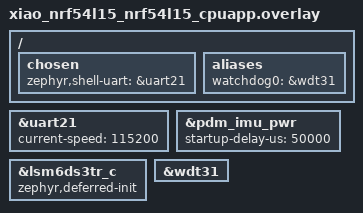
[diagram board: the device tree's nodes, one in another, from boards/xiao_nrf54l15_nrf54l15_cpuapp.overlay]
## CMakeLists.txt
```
#
# Copyright (c) 2021 Nordic Semiconductor ASA
#
# SPDX-License-Identifier: LicenseRef-Nordic-5-Clause
#

cmake_minimum_required(VERSION 3.20.0)

find_package(Zephyr HINTS $ENV{ZEPHYR_BASE})

project(nRF54l15_Bridge)

# Enable GNU STD support.
include(${ZEPHYR_CONNECTEDHOMEIP_MODULE_DIR}/config/nrfconnect/app/enable-gnu-std.cmake)

# NORDIC SDK APP START

# Include all source files that are located in the Matter common directory.
include(${ZEPHYR_NRF_MODULE_DIR}/samples/matter/common/cmake/source_common.cmake)

# Include Data Model utils
include(${ZEPHYR_NRF_MODULE_DIR}/samples/matter/common/cmake/data_model.cmake)

include(${ZEPHYR_NRF_MODULE_DIR}/samples/matter/common/cmake/zap_helpers.cmake)
ncs_get_zap_parent_dir(ZAP_PARENT_DIR)

target_include_directories(app PRIVATE
  src
  ${ZAP_PARENT_DIR}
)

target_sources(app PRIVATE
  src/app_task.cpp
  src/main.cpp
)

ncs_configure_data_model()
# NORDIC SDK APP END
```

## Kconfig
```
#
# Copyright (c) 2022 Nordic Semiconductor
#
# SPDX-License-Identifier: LicenseRef-Nordic-5-Clause
#
mainmenu "Matter nRF Connect Template Example Application"

# Sample configuration used for Thread networking
if OPENTHREAD

# Full Thread Device, not the template's minimal default.
#
# The bridge is mains-powered and hosts up to a hundred endpoints a controller
# subscribes to; it should keep its radio on and route for the mesh rather than
# sleep. An MTD cannot be a parent either, so anything downstream would have to
# reach the border router directly.
#
# This costs RAM: the router tables and the larger OpenThread library are a good
# part of why the previous project sat so close to the ceiling.
choice OPENTHREAD_NORDIC_LIBRARY_CONFIGURATION
	default OPENTHREAD_NORDIC_LIBRARY_FTD
endchoice

choice OPENTHREAD_DEVICE_TYPE
	default OPENTHREAD_FTD
endchoice

# SED with 0 dBm Thread TX output power for nRF54L15 tag
if BOARD_NRF54L15TAG

config CHIP_ENABLE_ICD_SUPPORT
	default y

config OPENTHREAD_DEFAULT_TX_POWER
	default 0

endif

endif # OPENTHREAD

config CHIP_WIFI
	default y if SHIELD_NRF7002EB2

menu "Matter bridge options"

config BRIDGE_MAX_ENDPOINTS
	int "Maximum number of bridged devices"
	default 8
	range 1 240
	help
	  Size of the bridge slot table and of the Matter dynamic endpoint
	  storage. Each slot costs RAM (endpoint record + data versions +
	  Matter attribute-storage metadata), so raising this is the main
	  lever on how many devices the board can host at once.

config BRIDGE_DEBUG_LOG
	bool "Verbose bridge debug logging"
	default y
	help
	  Emit extra informational logs from the bridge. Turn this off in
	  release builds (e.g. on RAM-constrained boards) to save memory.

menu "Bridged device types available to host"

config BRIDGE_TYPE_TEMPERATURE
	bool "Temperature sensor"
	default y

config BRIDGE_TYPE_HUMIDITY
	bool "Humidity sensor"
	default y

config BRIDGE_TYPE_ONOFF_LIGHT
	bool "On/Off light"
	default y

config BRIDGE_TYPE_CONTACT
	bool "Contact sensor"
	default y

config BRIDGE_TYPE_OCCUPANCY
	bool "Occupancy sensor"
	default y

config BRIDGE_TYPE_PRESSURE
	bool "Pressure sensor"
	default y

config BRIDGE_TYPE_FLOW
	bool "Flow sensor"
	default y

config BRIDGE_TYPE_ILLUMINANCE
	bool "Illuminance (light) sensor"
	default y

config BRIDGE_TYPE_WATER_LEAK
	bool "Water leak detector"
	default y

config BRIDGE_TYPE_ONOFF_PLUG
	bool "On/Off plug / outlet"
	default y

config BRIDGE_TYPE_DIMMABLE_LIGHT
	bool "Dimmable light"
	default y

config BRIDGE_TYPE_COLOR_LIGHT
	bool "Color temperature light"
	default y

config BRIDGE_TYPE_WINDOW_COVERING
	bool "Window covering (blinds / shades)"
	default y

config BRIDGE_TYPE_DOOR_LOCK
	bool "Door lock"
	default y

config BRIDGE_TYPE_RGB_LIGHT
	bool "Extended color (RGB) light"
	default y

config BRIDGE_TYPE_DIMMABLE_PLUG
	bool "Dimmable plug"
	default y

config BRIDGE_TYPE_THERMOSTAT
	bool "Thermostat"
	default y

config BRIDGE_TYPE_FAN
	bool "Fan"
	default y

config BRIDGE_TYPE_AIR_PURIFIER
	bool "Air purifier"
	default y

config BRIDGE_TYPE_AIR_QUALITY
	bool "Air quality sensor"
	default y

config BRIDGE_TYPE_SMOKE_CO
	bool "Smoke / CO alarm"
	default y

config BRIDGE_TYPE_WATER_VALVE
	bool "Water valve"
	default y

config BRIDGE_TYPE_WATER_FREEZE
	bool "Water freeze detector"
	default y

config BRIDGE_TYPE_RAIN
	bool "Rain sensor"
	default y

config BRIDGE_TYPE_ONOFF_SENSOR
	bool "On/Off sensor"
	default y

config BRIDGE_TYPE_MOUNTED_ONOFF
	bool "Mounted On/Off control"
	default y

config BRIDGE_TYPE_MOUNTED_DIMMER
	bool "Mounted dimmable load control"
	default y

config BRIDGE_TYPE_PUMP
	bool "Pump"
	default n

config BRIDGE_TYPE_COOKTOP
	bool "Cooktop"
	default n

config BRIDGE_TYPE_SPEAKER
	bool "Speaker (on/off + volume)"
	default n

config BRIDGE_TYPE_EXTRACTOR_HOOD
	bool "Extractor hood"
	default n

config BRIDGE_TYPE_ROOM_AC
	bool "Room air conditioner"
	default y

config BRIDGE_TYPE_HVAC_UNIT
	bool "Heating/cooling unit"
	default y

config BRIDGE_TYPE_HEAT_PUMP
	bool "Heat pump"
	default y

config BRIDGE_TYPE_WATER_HEATER
	bool "Water heater"
	default y

config BRIDGE_TYPE_SOIL
	bool "Soil sensor (moisture)"
	default y

comment "Stub device types (announced only, no functional clusters yet)"

config BRIDGE_TYPE_STUB_CONTROL
	bool "Stub: generic switch"
	default n

config BRIDGE_TYPE_STUB_ENERGY
	bool "Stub: energy devices (EVSE, solar, battery, meter, tariff, DEM)"
	default n

config BRIDGE_TYPE_STUB_APPLIANCE
	bool "Stub: appliances (vacuum, fridge, washer, dryer, dishwasher, oven...)"
	default n

config BRIDGE_TYPE_STUB_MEDIA
	bool "Stub: media devices (video players, content app)"
	default n

config BRIDGE_TYPE_STUB_CLOSURE
	bool "Stub: closures (Matter 1.5)"
	default n

config BRIDGE_TYPE_STUB_CAMERA
	bool "Stub: camera (Matter 1.5)"
	default n

endmenu # Bridged device types

menu "XIAO nRF54L15 Sense on-board sensors"
	depends on BOARD_XIAO_NRF54L15

config BRIDGE_XIAO_IMU
	bool "Vibration / drop detection from the on-board IMU (LSM6DSO)"
	# Ported switched off: the IMU is a later step of the rebuild, and pulling
	# the sensor driver in now would test two things at once.
	default n
	select SENSOR
	select I2C
	select LSM6DSL
	help
	  Samples the on-board 6-axis IMU and exposes the result as a bridged
	  occupancy (motion) endpoint. The accelerometer is used rather than the
	  microphone: it detects both shaking and an actual drop (free fall
	  followed by an impact), and it cannot be fooled by ambient noise.

if BRIDGE_XIAO_IMU

config BRIDGE_XIAO_IMU_AUTO_ENDPOINT
	bool "Create the vibration endpoint automatically on first boot"
	default y

config BRIDGE_XIAO_IMU_STACK_SIZE
	int "Stack size of the IMU sampling thread"
	default 2048
	help
	  The sampling loop takes the Matter stack lock and performs I2C
	  transfers, so it needs its own stack rather than the shared system
	  workqueue.

config BRIDGE_XIAO_IMU_PERIOD_MS
	int "Sampling period in milliseconds"
	default 50

config BRIDGE_XIAO_IMU_VIBRATION_MG
	int "Vibration threshold (milli-g deviation from 1 g at rest)"
	default 350

config BRIDGE_XIAO_IMU_FREEFALL_MG
	int "Free-fall threshold (milli-g, total acceleration)"
	default 300

config BRIDGE_XIAO_IMU_IMPACT_MG
	int "Impact threshold after free fall (milli-g)"
	default 2000

config BRIDGE_XIAO_IMU_HOLD_S
	int "How long the endpoint stays 'detected' after a trigger (seconds)"
	default 5

endif # BRIDGE_XIAO_IMU

config BRIDGE_XIAO_MIC
	bool "Build the on-board PDM microphone driver"
	default n
	select AUDIO
	select AUDIO_DMIC
	help
	  Build-time switch that pulls in the PDM microphone driver for the Sense
	  board. Nothing in the bridge consumes audio yet - vibration detection
	  uses the IMU - so this only adds the driver to the image.

endmenu # XIAO sensors

menu "Shell access"

config BRIDGE_AUX_SHELL
	bool "Serve a second shell on the other UART"
	depends on SHELL
	default n
	help
	  Zephyr binds its UART shell to `chosen { zephyr,shell-uart }` and only
	  ever creates one instance, so the two board overlays are an either/or
	  switch: commands arrive over USB or over the header pins, never both.

	  Enable this to bring up a second, independent shell on the UART named
	  by `chosen { bridge,cmd-uart }` - the overlays point it at whichever
	  port the main shell did not take. Both instances share the same command
	  set and keep their own line buffer and history, so the ESP companion on
	  the pins and a human on the USB console do not step on each other.

	  Costs roughly 3 KB of RAM (a shell thread plus its buffers).

if BRIDGE_AUX_SHELL

config BRIDGE_AUX_SHELL_PROMPT
	string "Prompt for the second shell"
	default "aux:~$ "
	help
	  Deliberately different from the main shell's "uart:~$ " so it is
	  obvious which port you are typing on.

config BRIDGE_AUX_SHELL_INIT_PRIORITY
	int "Init priority for the second shell"
	default 91
	range 0 99
	help
	  Must be higher than both the UART driver's priority and
	  SHELL_BACKEND_SERIAL_INIT_PRIORITY (which defaults to
	  APPLICATION_INIT_PRIORITY, 90), so the built-in shell finishes
	  claiming its port first.

endif # BRIDGE_AUX_SHELL

endmenu # Shell access

endmenu # Matter bridge options

source "$(ZEPHYR_CONNECTEDHOMEIP_MODULE_DIR)/config/nrfconnect/chip-module/Kconfig.features"
source "$(ZEPHYR_CONNECTEDHOMEIP_MODULE_DIR)/config/nrfconnect/chip-module/Kconfig.defaults"
source "$(ZEPHYR_NRF_MODULE_DIR)/samples/matter/common/src/Kconfig"
source "Kconfig.zephyr"
```

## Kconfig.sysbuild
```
#
# Copyright (c) 2023 Nordic Semiconductor ASA
#
# SPDX-License-Identifier: LicenseRef-Nordic-5-Clause
#

#### Radio core selection
config NRF_DEFAULT_IPC_RADIO
	default y

# Enable IEEE802.15.4 serialization to network core
# This config automatically pulls in the `overlay-802154.conf` in the ipc_radio image
config NETCORE_IPC_RADIO_IEEE802154
	default y if SOC_SERIES_NRF53 && !WIFI_NRF70

# Enable Bluetooth serialization to network core
# This config automatically pulls in the `overlay-bt_hci_ipc.conf` in the ipc_radio image
config NETCORE_IPC_RADIO_BT_HCI_IPC
	default y if SOC_SERIES_NRF53

#### Bootloader
#
# No MCUboot on the XIAO. The board has no external flash, so the secondary
# slot would have to come out of the same internal RRAM as the application, and
# DFU through it is not something this board can usefully do anyway. Left
# enabled it does not merely waste space: MCUboot itself halts in
# arch_system_halt before ever reaching the application. Building without a
# bootloader links the app at 0x0 and hands it the whole RRAM - which is what
# the previous working firmware did too.
choice BOOTLOADER
	default BOOTLOADER_NONE if BOARD_XIAO_NRF54L15
	default BOOTLOADER_MCUBOOT if !BOARD_NRF21540DK
endchoice

# Matter OTA goes with it. Sysbuild pushes CONFIG_CHIP_OTA_REQUESTOR into the
# application image (nrf/sysbuild/CMakeLists.txt), so setting it in a board
# fragment is useless - the value arrives via .config.sysbuild and wins. Without
# MCUboot the requestor fails to link on `dfu_target_mcuboot_set_buf`.
config MATTER_OTA
	default n if BOARD_XIAO_NRF54L15

if BOOTLOADER_MCUBOOT

#### DFU multi-image support
config DFU_MULTI_IMAGE_PACKAGE_BUILD
	default y

config DFU_MULTI_IMAGE_PACKAGE_APP
	default y

#### DFU network core configuration
if SOC_SERIES_NRF53

choice MCUBOOT_MODE
	default MCUBOOT_MODE_OVERWRITE_ONLY
endchoice

choice BOOT_SIGNATURE_TYPE
	default BOOT_SIGNATURE_TYPE_RSA
endchoice

config SECURE_BOOT_NETCORE
	default y

config NETCORE_APP_UPDATE
	default y

config DFU_MULTI_IMAGE_PACKAGE_NET
	default y

endif # SOC_SERIES_NRF53

endif # BOOTLOADER_MCUBOOT

#### Enable generating factory data
#
# The XIAO has no factory_data partition to write into - no external flash, and
# its layout does not carve one out - so the generator aborts during sysbuild
# configuration with "required nodelabel not found: factory_data_partition".
# The board falls back to the development certificates compiled into the
# firmware, which is what CONFIG_CHIP_FACTORY_DATA=n selects application-side.
config MATTER_FACTORY_DATA_GENERATE
	default y if !BOARD_NRF21540DK && !BOARD_XIAO_NRF54L15

# Internal flash only for nRF54L15 tag with compression
if BOARD_NRF54L15TAG

choice MCUBOOT_MODE
	default MCUBOOT_MODE_OVERWRITE_ONLY
endchoice

config MCUBOOT_COMPRESSED_IMAGE_SUPPORT
	default y

endif

# Partition Manager backwards compatibility
if PARTITION_MANAGER

if SOC_NRF54L10

config PM_MCUBOOT_PAD
	default 0x1000

endif # SOC_NRF54L10

if BOARD_NRF54L15TAG

config PM_OVERRIDE_EXTERNAL_DRIVER_CHECK
	default y

config PM_EXTERNAL_FLASH_MCUBOOT_SECONDARY
	default y

endif # BOARD_NRF54L15TAG

if BOARD_NRF54L15DK || BOARD_NRF54LM20DK

# Disable checking the external drivers for nRF54L15 and nRF54LM20 DKs.
config PM_OVERRIDE_EXTERNAL_DRIVER_CHECK
	default y

endif # BOARD_NRF54L15DK || BOARD_NRF54LM20DK

if BOOTLOADER_MCUBOOT

config PM_EXTERNAL_FLASH_MCUBOOT_SECONDARY
	default y

endif # BOOTLOADER_MCUBOOT

endif # PARTITION_MANAGER

source "share/sysbuild/Kconfig"
```

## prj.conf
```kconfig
#
# Copyright (c) 2021 Nordic Semiconductor ASA
#
# SPDX-License-Identifier: LicenseRef-Nordic-5-Clause
#

# This sample uses Kconfig.defaults to set options common for all
# samples. This file should contain only options specific for this sample
# or overrides of default values.

# Enable CHIP
CONFIG_CHIP=y
CONFIG_CHIP_PROJECT_CONFIG="src/chip_project_config.h"
CONFIG_CHIP_DEVICE_PRODUCT_NAME="Matter Template"

# Configure ZAP file name
CONFIG_NCS_SAMPLE_MATTER_ZAP_FILE_PATH="${APPLICATION_CONFIG_DIR}/src/default_zap/template.zap"

# 32768 == 0x8000 (example Product ID added temporaly,
# but it must be changed with proper PID from the list:
# https://github.com/project-chip/connectedhomeip/blob/482e6fd03196a6de45465a90003947ef4b86e0b1/docs/examples/discussion/PID_allocation_for_example_apps.md)
CONFIG_CHIP_DEVICE_PRODUCT_ID=32768
CONFIG_STD_CPP17=y

# Enable Matter pairing automatically on application start.
CONFIG_CHIP_ENABLE_PAIRING_AUTOSTART=y

# Enable Matter extended announcement and increase duration to 1 hour.
CONFIG_CHIP_BLE_EXT_ADVERTISING=y
CONFIG_CHIP_BLE_ADVERTISING_DURATION=60

# Add support for LEDs and buttons on Nordic development kits
CONFIG_DK_LIBRARY=y

# Bluetooth Low Energy configuration
CONFIG_BT_DEVICE_NAME="MatterTemplate"

# Other settings
CONFIG_THREAD_NAME=y
CONFIG_MPU_STACK_GUARD=y
CONFIG_RESET_ON_FATAL_ERROR=n
CONFIG_CHIP_LIB_SHELL=y
CONFIG_NCS_SAMPLE_MATTER_TEST_SHELL=y

# Disable NFC onboarding
CONFIG_CHIP_NFC_ONBOARDING_PAYLOAD=n

# Reduce application size
CONFIG_USE_SEGGER_RTT=n

# Factory data: off.
#
# Set here rather than in boards/xiao_nrf54l15_nrf54l15_cpuapp.conf because a
# board fragment does not win against an explicit assignment in prj.conf - the
# board file said =n and the build still came out =y.
#
# The XIAO has no factory_data partition (no external flash, and the layout
# does not carve one out), so the provider fails to compile at all:
# FactoryDataProvider.h needs DT_NODELABEL(factory_data_partition). Matter uses
# the development certificates compiled into the firmware instead.
# NOTE: CONFIG_CHIP_FACTORY_DATA=n does NOT work here. In NCS 3.4 the provider
# sits behind `choice CHIP_FACTORY_DATA_BACKEND`, whose default member selects
# CHIP_FACTORY_DATA - and a select cannot be overridden by =n in a fragment.
# Picking the "none" member of the choice is the supported way to turn it off.
# (In 3.2.3 there was no choice and plain =n was enough.)
CONFIG_CHIP_FACTORY_DATA_NONE=y
```

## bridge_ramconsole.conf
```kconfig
# Console into RAM, read out over SWD.
#
# For debugging only. Both UARTs on this board have been unreadable - the
# header pins go quiet and the USB console emits a handful of corrupt bytes at
# every baud rate - which meant Zephyr's fault dump, the one thing that says
# what actually crashed, was being written into a void. A RAM console does not
# care about clocks, pins or a debug chip's CDC: the text lands in a buffer at a
# known address and a debugger reads it out afterwards.
#
# Add as the last Extra Kconfig fragment; remove it for normal builds.
CONFIG_RAM_CONSOLE=y
CONFIG_RAM_CONSOLE_BUFFER_SIZE=4096

# The UART console must go, or it stays the active console driver and the RAM
# buffer never receives a byte - which looks exactly like "nothing was printed".
CONFIG_UART_CONSOLE=n
```

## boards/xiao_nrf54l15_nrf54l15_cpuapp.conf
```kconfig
# Seeed XIAO nRF54L15 (Sense) - application configuration.
#
# Picked up automatically by filename, no need to list it as an extra fragment.

# Factory data is switched off in prj.conf - see the note there, it has to be
# done through the backend choice rather than CONFIG_CHIP_FACTORY_DATA=n.

# CONFIG_LTO is deliberately NOT set.
#
# It was added early on to squeeze the image into MCUboot's 664 KB slot. Once
# the bootloader went away the whole RRAM became available and LTO was no
# longer needed - but it stayed, and it corrupts the linker-section table that
# net_buf pools are looked up through. The result was a BUS FAULT with
# BFAR 0xa inside pool_get_uninit on the MPSL Work thread, right after BLE
# init: net_buf_alloc_len being handed a null pool.
#
# It behaved like a memory bug - intermittent, and more frequent as the image
# grew - because that is how LTO decisions shift. Turning it off fixed it
# outright: first flash, clean boot, every time. Costs 52 KB of flash out of
# 1524 KB, which is not a trade worth revisiting.
CONFIG_ISR_TABLES_LOCAL_DECLARATION=y

# Consequences of building without MCUboot (see Kconfig.sysbuild).
#
# Matter's OTA requestor is written against MCUboot's DFU target; with no
# bootloader it still compiles but fails to link on
# `dfu_target_mcuboot_set_buf`. Both have to go together - this is a dependency
# of the bootloader choice, not a separate decision.
CONFIG_CHIP_BOOTLOADER_NONE=y
CONFIG_CHIP_OTA_REQUESTOR=n

# Shell tuning for a machine on the other end of the wire.
#
# The defaults are aimed at a person on a terminal; over a raw UART the escape
# sequences only get in the way of a parser. And `bridge add <type> <name>` or
# `bridge set <id> <v> <v2> <v3>` are long lines - the default command buffer
# truncates them.
CONFIG_SHELL_VT100_COLORS=n
CONFIG_SHELL_CMD_BUFF_SIZE=256

# The default 3168 bytes left next to nothing spare: `bridge pairing` added a
# couple of frames and the thread ran off the bottom of its own stack, taking
# the board down in MemManage on the very first call. Generating the onboarding
# codes is the deepest work any command here does, so the headroom is sized for
# that rather than for the shallowest one.
CONFIG_SHELL_STACK_SIZE=4096

# The actual cause of "the ESP sees nothing on the wire" before this board is
# paired to anything - not the board being broken, and not fixable by
# resetting either side of the link.
#
# Zephyr's shell thread runs at K_LOWEST_APPLICATION_THREAD_PRIO when nothing
# overrides it - one step above idle, below every other thread in this image.
# Zephyr's shell thread runs at K_LOWEST_APPLICATION_THREAD_PRIO when nothing
# overrides it - one step above idle, below every other thread in this image
# (BT/OpenThread sit at priorities 6-8). An uncommissioned board advertises
# over BLE continuously, which keeps those threads busy ahead of the shell on
# every scheduling decision, on a single core with no time-slicing across
# priority levels. The shell is not stuck; it simply never wins.
#
# Raised to 1 - one step below main(), clear of every BT/OpenThread thread,
# well short of the cooperative MPSL tier nothing preemptible can reach
# anyway. Verified over SWD (RAM-console build) that the node was genuinely
# losing the scheduling race, not crashed or starved outright - but the
# priority bump alone did not clear the symptom. The actual fix is
# architectural: BLE advertising now stays off until told to start (`bridge
# commission`) - see PORTING_NOTES.md and nrf_link.h's "deferred pairing"
# block. Left in place regardless: a correct, harmless improvement even
# though it was not sufficient by itself.
CONFIG_SHELL_THREAD_PRIORITY_OVERRIDE=y
CONFIG_SHELL_THREAD_PRIORITY=1

# How many bridged devices the board can host at once.
#
# Raised in stages during the rebuild - this is where the previous project
# died, so each step is flashed and verified before the next.
CONFIG_BRIDGE_MAX_ENDPOINTS=50

# Board identity.
#
# A controller keys an accessory on vendor+product+serial+discriminator, so the
# DK and the XIAO must not share them or a hub will treat the second board as
# the first one and refuse it.
#
# CONFIG_CHIP_DEVICE_DISCRIMINATOR is Kconfig type *hex*: writing =3840 means
# 0x3840 = 14400, which is outside the 12-bit range and aborts the application
# during QR generation. It has to be 0xF00.
CONFIG_CHIP_DEVICE_PRODUCT_NAME="Concordia One"
CONFIG_CHIP_DEVICE_VENDOR_NAME="Concordia"
CONFIG_CHIP_DEVICE_PRODUCT_ID=32770
CONFIG_CHIP_DEVICE_SERIAL_NUMBER="XIAO-54L15-0001"
CONFIG_CHIP_DEVICE_SOFTWARE_VERSION=1
CONFIG_CHIP_DEVICE_SOFTWARE_VERSION_STRING="Core One"
CONFIG_CHIP_DEVICE_HARDWARE_VERSION=1
CONFIG_CHIP_DEVICE_HARDWARE_VERSION_STRING="XIAO nRF54L15 Sense"
CONFIG_CHIP_DEVICE_MANUFACTURING_DATE="2026-01-01"
CONFIG_CHIP_DEVICE_DISCRIMINATOR=0xF00
CONFIG_CHIP_DEVICE_SPAKE2_PASSCODE=20202021
# Matter defaults BT_DEVICE_NAME_MAX to 15 and the BLE host checks the name
# against it at compile time, so a longer name fails the build outright rather
# than being truncated. This name is 37 characters.
CONFIG_BT_DEVICE_NAME="Concordia nRF54L15 Sense Xiao Edition"
CONFIG_BT_DEVICE_NAME_MAX=40

# OpenThread CLI in the image.
#
# `ot state`, `ot ipaddr`, `ot netdata show` and `ot ping` are the only way to
# tell a radio problem from an IPv6 routing one. That distinction is what
# eventually explained the old project's "offline in HomeKit": the board could
# ping the border router's ULA in 13 ms, and could not reach the global address
# Matter had picked - so the radio was never the problem. Reachable from the web
# console through the ESP, which makes it usable without a cable.
CONFIG_OPENTHREAD_SHELL=y

# Stack headroom and a guard, against the BUS FAULT / BFAR 0xa in MPSL Work.
#
# The fault reads a null net_buf pool pointer inside the radio's own thread,
# right after BLE init, and it is intermittent - it grew more frequent as the
# image grew, which is what a stack overflow into a neighbour's data looks like
# when the memory map shifts underneath it. The system workqueue's default
# 1120 bytes is thin for what this application puts on it.
CONFIG_SYSTEM_WORKQUEUE_STACK_SIZE=2048

# And make the next one say so: with the MPU guarding every stack, an overflow
# becomes an immediate "stack overflow" naming the guilty thread instead of
# silent corruption surfacing three subsystems away.
CONFIG_HW_STACK_PROTECTION=y

# On-board IMU (vibration / drop detection).
#
# No devicetree overlay is needed on 3.4.0 - the board files already declare the
# part as lsm6ds3tr_c / compatible "st,lsm6dsl" and point imu0 at it. Seeed's own
# zephyr-imu example notes that on the nRF54L15 the rail is already up
# (pdm_imu_pwr has regulator-boot-on) and the device auto-inits at boot.
CONFIG_BRIDGE_XIAO_IMU=y
CONFIG_REGULATOR=y
CONFIG_REGULATOR_FIXED=y

# ...but NOT the SoC-level regulator that CONFIG_REGULATOR otherwise drags in.
# It manages the chip's own power modes (note its HIBERNATE_MIN_UPTIME_MS
# companion), and enabling the IMU was crashing MPSL right after BLE init.
# Seeed's example gets away with it because it has no radio to destabilise.
CONFIG_REGULATOR_NRF54L=n

# ODR defaults to 0 = "runtime", which leaves the accelerometer powered down and
# every reading at 0 mg. 4 = 104 Hz.
CONFIG_LSM6DSL_ACCEL_ODR=4
CONFIG_LSM6DSL_ACCEL_FS=8

# Trim what is only there for debugging.
#
# The Matter test shell and the verbose logging were carried over from the
# template and cost RAM for nothing - the bridge has its own CLI and the ESP
# drives it. This is the profile the 3.2.3 firmware ran with.
# The bridge CLI needs the Zephyr shell, and until now it arrived for free as a
# side effect of the Matter shells. Turning those off takes it with them, so ask
# for it by name.
CONFIG_SHELL=y
CONFIG_CHIP_LIB_SHELL=n
CONFIG_NCS_SAMPLE_MATTER_TEST_SHELL=n
CONFIG_BRIDGE_DEBUG_LOG=n
CONFIG_MATTER_LOG_LEVEL_INF=y

# Hardware watchdog.
#
# Earned its place: an infinite loop in the IMU sampling thread once left the
# board burning CPU for hours, answering Matter but nothing else, with no way
# back except a manual reset. A watchdog turns that into a reboot.
CONFIG_NCS_SAMPLE_MATTER_WATCHDOG=y
```

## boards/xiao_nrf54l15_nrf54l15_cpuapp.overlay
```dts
/*
 * Seeed XIAO nRF54L15 (Sense).
 *
 * Picked up automatically by filename - deliberately, rather than as an extra
 * overlay passed on the command line. In the previous project the equivalent
 * settings lived in a fragment that had to be listed by hand, and a rebuild
 * that quietly omitted it produced a firmware whose endpoint limit had
 * collapsed from 100 to 8. Anything the board cannot work without belongs here.
 *
 * Note what is NOT here: the FLPR memory reclaim the 3.2.3 project carried
 * (&cpuapp_rram / &cpuapp_sram resized by hand). On NCS 3.4 the board already
 * reports the full 1524 KB RRAM and 256 KB SRAM without it. Adding it back
 * would be redrawing memory boundaries next to a radio that owns part of that
 * memory - which is what the old crashes looked like.
 */

/ {
	chosen {
		/*
		 * The interactive shell moves to the header pins so the ESP32-C6
		 * companion can drive `bridge ...` commands. The console stays on
		 * uart20 (USB) so logs remain separate from command output - a
		 * parser on the other end should never have to tell them apart.
		 *
		 *   uart20 -> P1.09 TX / P1.08 RX, wired to the on-board CMSIS-DAP
		 *   uart21 -> P2.08 TX / P2.07 RX, on the pin header
		 *
		 * Wiring (both boards are 3V3, common ground is mandatory):
		 *   nRF P2.08 --> ESP D3 (GPIO21, RX)
		 *   nRF P2.07 <-- ESP D2 (GPIO2,  TX)
		 *   nRF GND    -- ESP GND
		 */
		zephyr,shell-uart = &uart21;
	};
};

&uart21 {
	status = "okay";
	current-speed = <115200>;
};

/*
 * Give the IMU rail time to settle before the driver talks to it.
 *
 * The board file allows 5 ms. That is not enough for the LSM6DS3TR-C: the
 * driver's init does a software reboot of the chip over I2C and it was failing
 * with "failed to reboot device", so device_is_ready() stayed false and the
 * vibration endpoint was never created.
 *
 * It is a timing problem, not a wiring one - an `i2c scan` from the shell on a
 * board that has been up a while finds the part answering perfectly well at
 * 0x6a. The rail is confirmed on too: P0.01 reads back as a driven high.
 */
&pdm_imu_pwr {
	startup-delay-us = <50000>;
};

/*
 * Initialise the IMU from the application, not from the boot sequence.
 *
 * Even with the longer rail delay the driver's automatic init still failed, and
 * once it has failed device_is_ready() stays false forever - it reports the
 * result of that one attempt, it does not re-probe. Deferring means the boot
 * sequence leaves the part alone and the bridge calls device_init() itself,
 * seconds later, with the rail long settled. Seeed's own zephyr-imu example
 * uses exactly this shape for the board that needs its PMIC brought up first.
 */
&lsm6ds3tr_c {
	zephyr,deferred-init;
};

/* Watchdog for CONFIG_NCS_SAMPLE_MATTER_WATCHDOG: the sample code takes it
 * from the watchdog0 alias, and the board files do not define one. */
&wdt31 {
	status = "okay";
};

/ {
	aliases {
		watchdog0 = &wdt31;
	};
};
```

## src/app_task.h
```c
/*
 * Copyright (c) 2021 Nordic Semiconductor ASA
 *
 * SPDX-License-Identifier: LicenseRef-Nordic-5-Clause
 */

#pragma once

#include <platform/CHIPDeviceLayer.h>

struct k_timer;

class AppTask {
public:
	static AppTask &Instance()
	{
		static AppTask sAppTask;
		return sAppTask;
	};

	CHIP_ERROR StartApp();

private:
	CHIP_ERROR Init();
};
```

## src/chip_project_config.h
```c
/*
 * Copyright (c) 2021 Nordic Semiconductor ASA
 *
 * SPDX-License-Identifier: LicenseRef-Nordic-5-Clause
 */

/**
 *    @file
 *          Example project configuration file for CHIP.
 *
 *          This is a place to put application or project-specific overrides
 *          to the default configuration values for general CHIP features.
 *
 */

#pragma once

/* Number of bridged (dynamic) endpoints. Driven by CONFIG_BRIDGE_MAX_ENDPOINTS
 * so the bridge slot table and Matter's endpoint storage stay in sync - there
 * is a static_assert in app_task.cpp that fails loudly if they ever diverge. */
#define CHIP_DEVICE_CONFIG_DYNAMIC_ENDPOINT_COUNT CONFIG_BRIDGE_MAX_ENDPOINTS

/* Keep more than one resolved address for a peer.
 *
 * The default is 1: only the highest-scoring address survives resolution, and
 * IPAddressSorter ranks global unicast (4) above a ULA (3). This house's ISP
 * rotates its delegated prefix, so the hub keeps announcing a global address
 * that is already dead while its ULA stays reachable. With a single result the
 * CASE retry path - OperationalSessionSetup::TryNextResult, which is already
 * enabled - has nothing to fall back to: every handshake times out and the
 * bridge shows as offline while the radio is perfectly fine.
 *
 * This was diagnosed on the old hardware by pinging from the board: its own
 * ULA reached the border router in 13 ms, the hub's advertised global address
 * was unreachable from anywhere on the LAN, and the Matter log showed it being
 * chosen with "new best score: 4".
 *
 * Costs roughly 150 bytes per lookup handle. */
#define CHIP_CONFIG_MDNS_RESOLVE_LOOKUP_RESULTS 4
```
